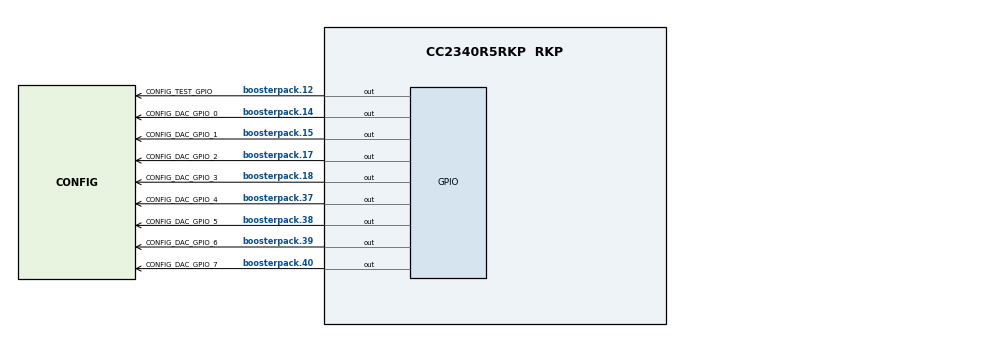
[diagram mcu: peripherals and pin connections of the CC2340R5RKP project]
/**
 * @cliArgs --board "/ti/boards/LP_EM_CC2340R5" --device "CC2340R5RKP" --part "Default" --package "RKP" --rtos "freertos" --product "simplelink_lowpower_f3_sdk@9.14.01.16"
 * @versions {"tool":"1.23.2+4156"}
 */

/**
 * Import the modules used in this configuration.
 */
const FreeRTOS  = scripting.addModule("/freertos/FreeRTOS");
const GPIO      = scripting.addModule("/ti/drivers/GPIO");
const GPIO1     = GPIO.addInstance();
const GPIO2     = GPIO.addInstance();
const GPIO3     = GPIO.addInstance();
const GPIO4     = GPIO.addInstance();
const GPIO5     = GPIO.addInstance();
const GPIO6     = GPIO.addInstance();
const GPIO7     = GPIO.addInstance();
const GPIO8     = GPIO.addInstance();
const GPIO9     = GPIO.addInstance();
const LGPTimer  = scripting.addModule("/ti/drivers/LGPTimer", {}, false);
const LGPTimer1 = LGPTimer.addInstance();
const Power     = scripting.addModule("/ti/drivers/Power");
const Settings  = scripting.addModule("/ti/posix/freertos/Settings");

/**
 * Write custom configuration values to the imported modules.
 */
GPIO1.$name           = "CONFIG_DAC_GPIO_0";
GPIO1.mode            = "Output";
GPIO1.outputStrength  = "High";
GPIO1.gpioPin.$assign = "boosterpack.14";

GPIO2.$name           = "CONFIG_DAC_GPIO_1";
GPIO2.mode            = "Output";
GPIO2.outputStrength  = "High";
GPIO2.gpioPin.$assign = "boosterpack.15";

GPIO3.$name           = "CONFIG_DAC_GPIO_2";
GPIO3.mode            = "Output";
GPIO3.outputStrength  = "High";
GPIO3.gpioPin.$assign = "boosterpack.17";

GPIO4.$name           = "CONFIG_DAC_GPIO_3";
GPIO4.mode            = "Output";
GPIO4.outputStrength  = "High";
GPIO4.gpioPin.$assign = "boosterpack.18";

GPIO5.$name           = "CONFIG_DAC_GPIO_4";
GPIO5.mode            = "Output";
GPIO5.outputStrength  = "High";
GPIO5.gpioPin.$assign = "boosterpack.37";

GPIO6.$name           = "CONFIG_DAC_GPIO_5";
GPIO6.mode            = "Output";
GPIO6.outputStrength  = "High";
GPIO6.gpioPin.$assign = "boosterpack.38";

GPIO7.$name           = "CONFIG_DAC_GPIO_6";
GPIO7.mode            = "Output";
GPIO7.outputStrength  = "High";
GPIO7.gpioPin.$assign = "boosterpack.39";

GPIO8.$name           = "CONFIG_DAC_GPIO_7";
GPIO8.mode            = "Output";
GPIO8.outputStrength  = "High";
GPIO8.gpioPin.$assign = "boosterpack.40";

GPIO9.mode            = "Output";
GPIO9.outputStrength  = "High";
GPIO9.$name           = "CONFIG_TEST_GPIO";
GPIO9.gpioPin.$assign = "boosterpack.12";

LGPTimer1.$name         = "CONFIG_LGPTIMER_0";
LGPTimer1.timer.$assign = "LGPT3";

const CCFG              = scripting.addModule("/ti/devices/CCFG", {}, false);
CCFG.ccfgTemplate.$name = "ti_devices_CCFG_CCFGCC23X0Template0";
